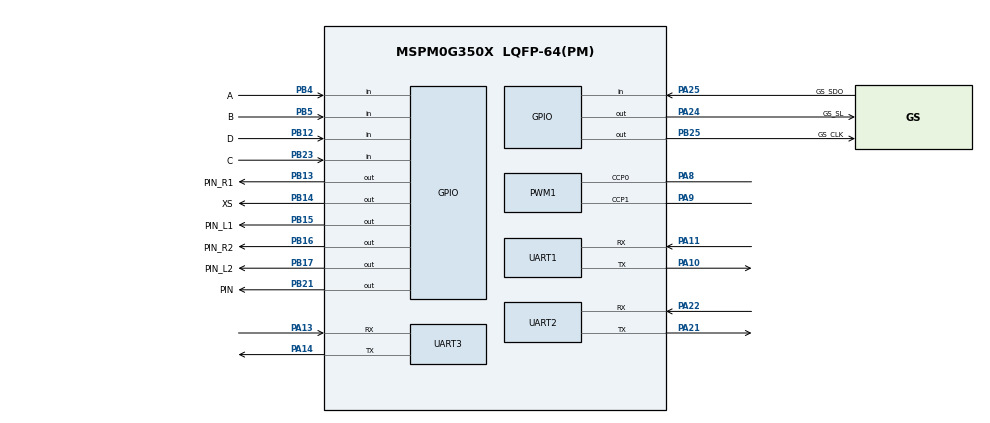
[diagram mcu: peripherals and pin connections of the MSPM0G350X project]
/**
 * @cliArgs --device "MSPM0G350X" --part "Default" --package "LQFP-64(PM)" --product "mspm0_sdk@2.07.00.06"
 * @versions {"tool":"1.25.0+4268"}
 */

/**
 * Import the modules used in this configuration.
 */
const ADC12   = scripting.addModule("/ti/driverlib/ADC12", {}, false);
const ADC121  = ADC12.addInstance();
const GPIO    = scripting.addModule("/ti/driverlib/GPIO", {}, false);
const GPIO1   = GPIO.addInstance();
const GPIO2   = GPIO.addInstance();
const GPIO3   = GPIO.addInstance();
const GPIO4   = GPIO.addInstance();
const GPIO5   = GPIO.addInstance();
const GPIO6   = GPIO.addInstance();
const GPIO7   = GPIO.addInstance();
const GPIO8   = GPIO.addInstance();
const GPIO9   = GPIO.addInstance();
const GPIO10  = GPIO.addInstance();
const PWM     = scripting.addModule("/ti/driverlib/PWM", {}, false);
const PWM1    = PWM.addInstance();
const SYSCTL  = scripting.addModule("/ti/driverlib/SYSCTL");
const SYSTICK = scripting.addModule("/ti/driverlib/SYSTICK");
const TIMER   = scripting.addModule("/ti/driverlib/TIMER", {}, false);
const TIMER1  = TIMER.addInstance();
const UART    = scripting.addModule("/ti/driverlib/UART", {}, false);
const UART1   = UART.addInstance();
const UART2   = UART.addInstance();
const UART3   = UART.addInstance();

/**
 * Write custom configuration values to the imported modules.
 */
ADC121.$name                             = "ADC_KEY";
ADC121.powerDownMode                     = "DL_ADC12_POWER_DOWN_MODE_MANUAL";
ADC121.samplingOperationMode             = "sequence";
ADC121.endAdd                            = 1;
ADC121.sampleTime0                       = "125us";
ADC121.adcMem1chansel                    = "DL_ADC12_INPUT_CHAN_0";
ADC121.adcMem0chansel                    = "DL_ADC12_INPUT_CHAN_5";
ADC121.peripheral.$assign                = "ADC0";
ADC121.peripheral.adcPin0.$assign        = "PA27";
ADC121.peripheral.adcPin5.$assign        = "PB24";
ADC121.adcPin0Config.$name               = "ti_driverlib_gpio_GPIOPinGeneric11";
ADC121.adcPin0Config.hideOutputInversion = scripting.forceWrite(false);
ADC121.adcPin0Config.enableConfig        = true;
ADC121.adcPin5Config.$name               = "ti_driverlib_gpio_GPIOPinGeneric0";
ADC121.adcPin5Config.hideOutputInversion = scripting.forceWrite(false);
ADC121.adcPin5Config.enableConfig        = true;

const mux2       = system.clockTree["CANCLKMUX"];
mux2.inputSelect = "CANCLKMUX_PLLCLK1_OUT";

GPIO1.$name                              = "LED";
GPIO1.port                               = "PORTB";
GPIO1.associatedPins[0].$name            = "PIN_22";
GPIO1.associatedPins[0].assignedPin      = "22";
GPIO1.associatedPins[0].internalResistor = "PULL_DOWN";

const Board = scripting.addModule("/ti/driverlib/Board", {}, false);

GPIO2.$name                              = "OLED";
GPIO2.port                               = "PORTB";
GPIO2.associatedPins.create(2);
GPIO2.associatedPins[0].$name            = "SCL";
GPIO2.associatedPins[0].initialValue     = "CLEARED";
GPIO2.associatedPins[0].assignedPin      = "9";
GPIO2.associatedPins[0].internalResistor = "PULL_UP";
GPIO2.associatedPins[1].$name            = "SDA";
GPIO2.associatedPins[1].initialValue     = "CLEARED";
GPIO2.associatedPins[1].assignedPin      = "8";
GPIO2.associatedPins[1].internalResistor = "PULL_UP";

GPIO3.$name                          = "GPIO_MOTOR";
GPIO3.associatedPins.create(4);
GPIO3.associatedPins[0].$name        = "PIN_L1";
GPIO3.associatedPins[0].assignedPort = "PORTB";
GPIO3.associatedPins[0].assignedPin  = "15";
GPIO3.associatedPins[0].pin.$assign  = "PB15";
GPIO3.associatedPins[1].$name        = "PIN_L2";
GPIO3.associatedPins[1].assignedPort = "PORTB";
GPIO3.associatedPins[1].assignedPin  = "17";
GPIO3.associatedPins[1].pin.$assign  = "PB17";
GPIO3.associatedPins[2].$name        = "PIN_R1";
GPIO3.associatedPins[2].assignedPort = "PORTB";
GPIO3.associatedPins[2].assignedPin  = "13";
GPIO3.associatedPins[2].pin.$assign  = "PB13";
GPIO3.associatedPins[3].$name        = "PIN_R2";
GPIO3.associatedPins[3].assignedPort = "PORTB";
GPIO3.associatedPins[3].assignedPin  = "16";
GPIO3.associatedPins[3].pin.$assign  = "PB16";

GPIO4.$name                               = "Encoder";
GPIO4.port                                = "PORTB";
GPIO4.associatedPins.create(4);
GPIO4.associatedPins[0].$name             = "A";
GPIO4.associatedPins[0].assignedPin       = "4";
GPIO4.associatedPins[0].direction         = "INPUT";
GPIO4.associatedPins[0].internalResistor  = "PULL_UP";
GPIO4.associatedPins[0].interruptEn       = true;
GPIO4.associatedPins[0].interruptPriority = "0";
GPIO4.associatedPins[0].polarity          = "RISE";
GPIO4.associatedPins[0].pin.$assign       = "PB4";
GPIO4.associatedPins[1].$name             = "B";
GPIO4.associatedPins[1].direction         = "INPUT";
GPIO4.associatedPins[1].assignedPin       = "5";
GPIO4.associatedPins[1].internalResistor  = "PULL_UP";
GPIO4.associatedPins[1].interruptEn       = true;
GPIO4.associatedPins[1].interruptPriority = "0";
GPIO4.associatedPins[1].polarity          = "RISE";
GPIO4.associatedPins[1].pin.$assign       = "PB5";
GPIO4.associatedPins[2].$name             = "C";
GPIO4.associatedPins[2].direction         = "INPUT";
GPIO4.associatedPins[2].assignedPin       = "23";
GPIO4.associatedPins[2].internalResistor  = "PULL_UP";
GPIO4.associatedPins[2].interruptEn       = true;
GPIO4.associatedPins[2].interruptPriority = "0";
GPIO4.associatedPins[2].polarity          = "RISE";
GPIO4.associatedPins[2].pin.$assign       = "PB23";
GPIO4.associatedPins[3].$name             = "D";
GPIO4.associatedPins[3].direction         = "INPUT";
GPIO4.associatedPins[3].assignedPin       = "12";
GPIO4.associatedPins[3].internalResistor  = "PULL_UP";
GPIO4.associatedPins[3].interruptEn       = true;
GPIO4.associatedPins[3].interruptPriority = "0";
GPIO4.associatedPins[3].polarity          = "RISE";
GPIO4.associatedPins[3].pin.$assign       = "PB12";

GPIO5.$name                               = "Encoder_XZ";
GPIO5.associatedPins.create(2);
GPIO5.associatedPins[0].$name             = "XZ_A";
GPIO5.associatedPins[0].direction         = "INPUT";
GPIO5.associatedPins[0].assignedPort      = "PORTA";
GPIO5.associatedPins[0].assignedPin       = "30";
GPIO5.associatedPins[0].internalResistor  = "PULL_UP";
GPIO5.associatedPins[0].interruptEn       = true;
GPIO5.associatedPins[0].interruptPriority = "1";
GPIO5.associatedPins[0].polarity          = "RISE";
GPIO5.associatedPins[1].$name             = "XZ_B";
GPIO5.associatedPins[1].direction         = "INPUT";
GPIO5.associatedPins[1].assignedPort      = "PORTA";
GPIO5.associatedPins[1].assignedPin       = "31";
GPIO5.associatedPins[1].internalResistor  = "PULL_UP";
GPIO5.associatedPins[1].interruptEn       = true;
GPIO5.associatedPins[1].interruptPriority = "1";
GPIO5.associatedPins[1].polarity          = "RISE";

GPIO6.$name                          = "Beep";
GPIO6.associatedPins[0].$name        = "PIN";
GPIO6.associatedPins[0].assignedPort = "PORTB";
GPIO6.associatedPins[0].assignedPin  = "21";
GPIO6.associatedPins[0].pin.$assign  = "PB21";

GPIO7.$name                          = "Key";
GPIO7.associatedPins.create(2);
GPIO7.associatedPins[0].$name        = "F1";
GPIO7.associatedPins[0].direction    = "INPUT";
GPIO7.associatedPins[0].assignedPort = "PORTA";
GPIO7.associatedPins[0].assignedPin  = "28";
GPIO7.associatedPins[1].$name        = "F2";
GPIO7.associatedPins[1].direction    = "INPUT";
GPIO7.associatedPins[1].assignedPort = "PORTA";
GPIO7.associatedPins[1].assignedPin  = "29";

GPIO8.$name                          = "IIC_Software";
GPIO8.port                           = "PORTA";
GPIO8.associatedPins.create(2);
GPIO8.associatedPins[0].$name        = "IIC_SCL";
GPIO8.associatedPins[0].initialValue = "SET";
GPIO8.associatedPins[0].ioStructure  = "OD";
GPIO8.associatedPins[0].assignedPort = "PORTA";
GPIO8.associatedPins[0].assignedPin  = "1";
GPIO8.associatedPins[1].$name        = "IIC_SDA";
GPIO8.associatedPins[1].ioStructure  = "OD";
GPIO8.associatedPins[1].initialValue = "SET";
GPIO8.associatedPins[1].assignedPort = "PORTA";
GPIO8.associatedPins[1].assignedPin  = "0";

/* ==== 8道灰度传感器 (74HC165 并进串出) ==== */
GPIO9.$name                              = "DataCollect";
GPIO9.associatedPins.create(3);
GPIO9.associatedPins[0].$name            = "GS_CLK";
GPIO9.associatedPins[0].internalResistor = "PULL_DOWN";
GPIO9.associatedPins[0].pin.$assign      = "PB25";
GPIO9.associatedPins[1].$name            = "GS_SL";
GPIO9.associatedPins[1].internalResistor = "PULL_UP";
GPIO9.associatedPins[1].pin.$assign      = "PA24";
GPIO9.associatedPins[2].$name            = "GS_SDO";
GPIO9.associatedPins[2].direction        = "INPUT";
GPIO9.associatedPins[2].pin.$assign      = "PA25";

GPIO10.$name                          = "DL1B";
GPIO10.port                           = "PORTB";
GPIO10.associatedPins[0].$name        = "XS";
GPIO10.associatedPins[0].initialValue = "SET";
GPIO10.associatedPins[0].assignedPin  = "14";
GPIO10.associatedPins[0].pin.$assign  = "PB14";

PWM1.$name                              = "PWM_MOTOR";
PWM1.timerCount                         = 2000;
PWM1.clockPrescale                      = 32;
PWM1.timerStartTimer                    = false;
PWM1.pwmMode                            = "EDGE_ALIGN_UP";
PWM1.peripheral.ccp0Pin.$assign         = "PA8";
PWM1.peripheral.ccp1Pin.$assign         = "PA9";
PWM1.PWM_CHANNEL_0.$name                = "ti_driverlib_pwm_PWMTimerCC0";
PWM1.PWM_CHANNEL_1.$name                = "ti_driverlib_pwm_PWMTimerCC1";
PWM1.ccp0PinConfig.direction            = scripting.forceWrite("OUTPUT");
PWM1.ccp0PinConfig.hideOutputInversion  = scripting.forceWrite(false);
PWM1.ccp0PinConfig.onlyInternalResistor = scripting.forceWrite(false);
PWM1.ccp0PinConfig.passedPeripheralType = scripting.forceWrite("Digital");
PWM1.ccp0PinConfig.$name                = "ti_driverlib_gpio_GPIOPinGeneric5";
PWM1.ccp1PinConfig.direction            = scripting.forceWrite("OUTPUT");
PWM1.ccp1PinConfig.hideOutputInversion  = scripting.forceWrite(false);
PWM1.ccp1PinConfig.onlyInternalResistor = scripting.forceWrite(false);
PWM1.ccp1PinConfig.passedPeripheralType = scripting.forceWrite("Digital");
PWM1.ccp1PinConfig.$name                = "ti_driverlib_gpio_GPIOPinGeneric6";

SYSCTL.forceDefaultClkConfig = true;

SYSTICK.periodEnable      = true;
SYSTICK.period            = 32000;
SYSTICK.interruptEnable   = true;
SYSTICK.systickEnable     = true;
SYSTICK.interruptPriority = "0";

TIMER1.$name              = "TIMER_1";
TIMER1.timerClkDiv        = 4;
TIMER1.timerClkPrescale   = 80;
TIMER1.timerMode          = "PERIODIC";
TIMER1.timerPeriod        = "1 ms";
TIMER1.timerStartTimer    = false;
TIMER1.interrupts         = ["ZERO"];
TIMER1.interruptPriority  = "0";
TIMER1.peripheral.$assign = "TIMA1";

UART1.$name                    = "UART_0";
UART1.targetBaudRate           = 115200;
UART1.enabledInterrupts        = ["RX"];
UART1.peripheral.$assign       = "UART0";
UART1.peripheral.rxPin.$assign = "PA11";
UART1.peripheral.txPin.$assign = "PA10";
UART1.txPinConfig.$name        = "ti_driverlib_gpio_GPIOPinGeneric3";
UART1.rxPinConfig.$name        = "ti_driverlib_gpio_GPIOPinGeneric4";

UART2.$name                            = "UART_2";
UART2.enabledInterrupts                = ["RX"];
UART2.peripheral.$assign               = "UART2";
UART2.peripheral.rxPin.$assign         = "PA22";
UART2.peripheral.txPin.$assign         = "PA21";
UART2.txPinConfig.direction            = scripting.forceWrite("OUTPUT");
UART2.txPinConfig.hideOutputInversion  = scripting.forceWrite(false);
UART2.txPinConfig.onlyInternalResistor = scripting.forceWrite(false);
UART2.txPinConfig.passedPeripheralType = scripting.forceWrite("Digital");
UART2.txPinConfig.$name                = "ti_driverlib_gpio_GPIOPinGeneric7";
UART2.rxPinConfig.hideOutputInversion  = scripting.forceWrite(false);
UART2.rxPinConfig.internalResistor     = "PULL_UP";
UART2.rxPinConfig.onlyInternalResistor = scripting.forceWrite(false);
UART2.rxPinConfig.passedPeripheralType = scripting.forceWrite("Digital");
UART2.rxPinConfig.$name                = "ti_driverlib_gpio_GPIOPinGeneric8";

/* ==== UART3 灰度传感器数据上传 (115200) ==== */
UART3.$name                            = "UART_3";
UART3.targetBaudRate                   = 115200;
UART3.peripheral.$assign               = "UART3";
UART3.peripheral.txPin.$assign         = "PA14";
UART3.peripheral.rxPin.$assign         = "PA13";
UART3.txPinConfig.direction            = scripting.forceWrite("OUTPUT");
UART3.txPinConfig.hideOutputInversion  = scripting.forceWrite(false);
UART3.txPinConfig.onlyInternalResistor = scripting.forceWrite(false);
UART3.txPinConfig.passedPeripheralType = scripting.forceWrite("Digital");
UART3.txPinConfig.$name                = "ti_driverlib_gpio_GPIOPinGeneric9";
UART3.rxPinConfig.hideOutputInversion  = scripting.forceWrite(false);
UART3.rxPinConfig.onlyInternalResistor = scripting.forceWrite(false);
UART3.rxPinConfig.passedPeripheralType = scripting.forceWrite("Digital");
UART3.rxPinConfig.$name                = "ti_driverlib_gpio_GPIOPinGeneric10";

/**
 * Pinmux solution for unlocked pins/peripherals. This ensures that minor changes to the automatic solver in a future
 * version of the tool will not impact the pinmux you originally saw.  These lines can be completely deleted in order to
 * re-solve from scratch.
 */
GPIO1.associatedPins[0].pin.$suggestSolution = "PB22";
Board.peripheral.$suggestSolution            = "DEBUGSS";
Board.peripheral.swclkPin.$suggestSolution   = "PA20";
Board.peripheral.swdioPin.$suggestSolution   = "PA19";
GPIO2.associatedPins[0].pin.$suggestSolution = "PB9";
GPIO2.associatedPins[1].pin.$suggestSolution = "PB8";
GPIO5.associatedPins[0].pin.$suggestSolution = "PA30";
GPIO5.associatedPins[1].pin.$suggestSolution = "PA31";
GPIO7.associatedPins[0].pin.$suggestSolution = "PA28";
GPIO7.associatedPins[1].pin.$suggestSolution = "PA29";
GPIO8.associatedPins[0].pin.$suggestSolution = "PA1";
GPIO8.associatedPins[1].pin.$suggestSolution = "PA0";
GPIO9.associatedPins[0].pin.$suggestSolution = "PB25";
GPIO9.associatedPins[1].pin.$suggestSolution = "PA24";
GPIO9.associatedPins[2].pin.$suggestSolution = "PA25";
GPIO10.associatedPins[0].pin.$suggestSolution = "PB14";
ADC121.peripheral.adcPin0.$suggestSolution    = "PA27";
UART3.peripheral.txPin.$suggestSolution      = "PA14";
UART3.peripheral.rxPin.$suggestSolution      = "PA13";
PWM1.peripheral.$suggestSolution             = "TIMA0";
SYSCTL.peripheral.$suggestSolution           = "SYSCTL";
